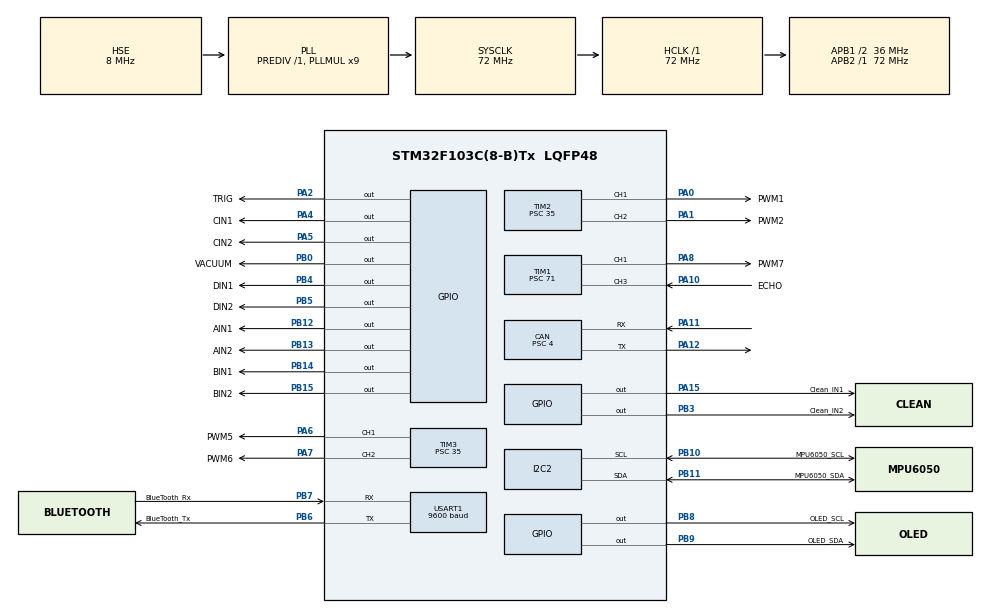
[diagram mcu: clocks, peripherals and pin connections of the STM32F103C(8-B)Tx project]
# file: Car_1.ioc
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CAN.ABOM=DISABLE
CAN.BS1=CAN_BS1_11TQ
CAN.BS2=CAN_BS2_6TQ
CAN.CalculateBaudRate=500000
CAN.CalculateTimeBit=2000
CAN.CalculateTimeQuantum=111.11111111111111
CAN.NART=DISABLE
CAN.Prescaler=4
I2C2.I2C_Mode=I2C_Fast
Mcu.Family=STM32F1
Mcu.Name=STM32F103C(8-B)Tx
Mcu.Package=LQFP48
NVIC.I2C2_EV_IRQn=true\:0\:0\:false\:false\:true\:true\:true\:true
NVIC.PriorityGroup=NVIC_PRIORITYGROUP_4
NVIC.USART1_IRQn=true\:0\:0\:false\:false\:true\:true\:true\:true
NVIC.USB_LP_CAN1_RX0_IRQn=true\:0\:0\:false\:false\:true\:true\:true\:true
PA0-WKUP.GPIO_Label=PWM1
PA0-WKUP.GPIO_Speed=GPIO_SPEED_FREQ_HIGH
PA0-WKUP.Signal=S_TIM2_CH1_ETR
PA1.GPIO_Label=PWM2
PA1.GPIO_Speed=GPIO_SPEED_FREQ_HIGH
PA1.Signal=S_TIM2_CH2
PA10.GPIO_Label=ECHO
PA10.Signal=S_TIM1_CH3
PA11.Mode=CAN_Activate
PA11.Signal=CAN_RX
PA12.Mode=CAN_Activate
PA12.Signal=CAN_TX
PA13.Mode=Serial_Wire
PA13.Signal=SYS_JTMS-SWDIO
PA14.Mode=Serial_Wire
PA14.Signal=SYS_JTCK-SWCLK
PA15.GPIO_Label=Clean_IN1
PA15.Signal=GPIO_Output
PA2.GPIO_Label=TRIG
PA2.Signal=GPIO_Output
PA4.GPIO_Label=CIN1
PA4.Signal=GPIO_Output
PA5.GPIO_Label=CIN2
PA5.Signal=GPIO_Output
PA6.GPIO_Label=PWM5
PA6.GPIO_Speed=GPIO_SPEED_FREQ_HIGH
PA6.Signal=S_TIM3_CH1
PA7.GPIO_Label=PWM6
PA7.GPIO_Speed=GPIO_SPEED_FREQ_HIGH
PA7.Signal=S_TIM3_CH2
PA8.GPIO_Label=PWM7
PA8.GPIO_Speed=GPIO_SPEED_FREQ_HIGH
PA8.Signal=S_TIM1_CH1
PB0.GPIO_Label=VACUUM
PB0.Signal=GPIO_Output
PB10.GPIO_Label=MPU6050_SCL
PB10.Mode=I2C
PB10.Signal=I2C2_SCL
PB11.GPIO_Label=MPU6050_SDA
PB11.Mode=I2C
PB11.Signal=I2C2_SDA
PB12.GPIO_Label=AIN1
PB12.Signal=GPIO_Output
PB13.GPIO_Label=AIN2
PB13.Signal=GPIO_Output
PB14.GPIO_Label=BIN1
PB14.Signal=GPIO_Output
PB15.GPIO_Label=BIN2
PB15.Signal=GPIO_Output
PB3.GPIO_Label=Clean_IN2
PB3.Signal=GPIO_Output
PB4.GPIO_Label=DIN1
PB4.Signal=GPIO_Output
PB5.GPIO_Label=DIN2
PB5.Signal=GPIO_Output
PB6.GPIO_Label=BlueTooth_Tx
PB6.Mode=Asynchronous
PB6.Signal=USART1_TX
PB7.GPIO_Label=BlueTooth_Rx
PB7.Mode=Asynchronous
PB7.Signal=USART1_RX
PB8.GPIO_Label=OLED_SCL
PB8.GPIO_ModeDefaultOutputPP=GPIO_MODE_OUTPUT_OD
PB8.GPIO_PuPd=GPIO_PULLUP
PB8.GPIO_Speed=GPIO_SPEED_FREQ_HIGH
PB8.PinState=GPIO_PIN_SET
PB8.Signal=GPIO_Output
PB9.GPIO_Label=OLED_SDA
PB9.GPIO_ModeDefaultOutputPP=GPIO_MODE_OUTPUT_OD
PB9.GPIO_PuPd=GPIO_PULLUP
PB9.GPIO_Speed=GPIO_SPEED_FREQ_HIGH
PB9.PinState=GPIO_PIN_SET
PB9.Signal=GPIO_Output
PC14-OSC32_IN.Mode=LSE-External-Oscillator
PC14-OSC32_IN.Signal=RCC_OSC32_IN
PC15-OSC32_OUT.Mode=LSE-External-Oscillator
PC15-OSC32_OUT.Signal=RCC_OSC32_OUT
PD0-OSC_IN.Mode=HSE-External-Oscillator
PD0-OSC_IN.Signal=RCC_OSC_IN
PD1-OSC_OUT.Mode=HSE-External-Oscillator
PD1-OSC_OUT.Signal=RCC_OSC_OUT
ProjectManager.HeapSize=0x200
ProjectManager.StackSize=0x400
ProjectManager.TargetToolchain=MDK-ARM V5.32
RCC.AHBFreq_Value=72000000
RCC.APB1CLKDivider=RCC_HCLK_DIV2
RCC.APB1Freq_Value=36000000
RCC.APB1TimFreq_Value=72000000
RCC.APB2Freq_Value=72000000
RCC.APB2TimFreq_Value=72000000
RCC.HCLKFreq_Value=72000000
RCC.PLLMUL=RCC_PLL_MUL9
RCC.PLLSourceVirtual=RCC_PLLSOURCE_HSE
RCC.SYSCLKFreq_VALUE=72000000
RCC.SYSCLKSource=RCC_SYSCLKSOURCE_PLLCLK
RCC.USBFreq_Value=72000000
SH.S_TIM1_CH1.0=TIM1_CH1,PWM Generation1 CH1
SH.S_TIM1_CH3.0=TIM1_CH3,Input_Capture3_from_TI3
SH.S_TIM2_CH1_ETR.0=TIM2_CH1,PWM Generation1 CH1
SH.S_TIM2_CH2.0=TIM2_CH2,PWM Generation2 CH2
SH.S_TIM3_CH1.0=TIM3_CH1,PWM Generation1 CH1
SH.S_TIM3_CH2.0=TIM3_CH2,PWM Generation2 CH2
TIM1.Channel-Input_Capture3_from_TI3=TIM_CHANNEL_3
TIM1.Channel-Input_Capture4_from_TI3_63=TIM_CHANNEL_4
TIM1.Channel-PWM\ Generation1\ CH1=TIM_CHANNEL_1
TIM1.ICPolarity_CH4=TIM_INPUTCHANNELPOLARITY_FALLING
TIM1.Period=19999
TIM1.Prescaler=71
TIM2.AutoReloadPreload=TIM_AUTORELOAD_PRELOAD_ENABLE
TIM2.Channel-PWM\ Generation1\ CH1=TIM_CHANNEL_1
TIM2.Channel-PWM\ Generation2\ CH2=TIM_CHANNEL_2
TIM2.Period=99
TIM2.Prescaler=35
TIM3.Channel-PWM\ Generation1\ CH1=TIM_CHANNEL_1
TIM3.Channel-PWM\ Generation2\ CH2=TIM_CHANNEL_2
TIM3.Period=99
TIM3.Prescaler=35
USART1.BaudRate=9600
USART1.VirtualMode=VM_ASYNC
VP_TIM1_VS_indirect_ch3.Mode=Input_Capture4_from_TI3_63
board=custom

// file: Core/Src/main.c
/* USER CODE BEGIN Header */
/**
  ******************************************************************************
  * @file           : main.c
  * @brief          : Main program body
  ******************************************************************************
  * @attention
  *
  * Copyright (c) 2026 STMicroelectronics.
  * All rights reserved.
  *
  * This software is licensed under terms that can be found in the LICENSE file
  * in the root directory of this software component.
  * If no LICENSE file comes with this software, it is provided AS-IS.
  *
  ******************************************************************************
  */
/* USER CODE END Header */
#include "main.h"
#include "can.h"
#include "i2c.h"
#include "tim.h"
#include "usart.h"
#include "gpio.h"

/* USER CODE BEGIN Includes */
#include "FreeRTOS_Task.h"
#include "OLED.h"
/* USER CODE END Includes */

void SystemClock_Config(void);

int main(void)
{

  /* MCU Configuration--------------------------------------------------------*/

  /* Reset of all peripherals, Initializes the Flash interface and the Systick. */
  HAL_Init();

  /* Configure the system clock */
  SystemClock_Config();

  /* Initialize all configured peripherals */
  MX_GPIO_Init();
  MX_USART1_UART_Init();
  MX_TIM1_Init();
  MX_TIM2_Init();
  MX_TIM3_Init();
  MX_I2C2_Init();
  MX_CAN_Init();
  /* USER CODE BEGIN 2 */

  //启动FreeRTOS => 后续的代码都不执行
  FreeRTOS_start();

  /* USER CODE END 2 */

  /* Infinite loop */
  while (1)
  {

  }
}

void SystemClock_Config(void)
{
  RCC_OscInitTypeDef RCC_OscInitStruct = {0};
  RCC_ClkInitTypeDef RCC_ClkInitStruct = {0};

  /** Initializes the RCC Oscillators according to the specified parameters
  * in the RCC_OscInitTypeDef structure.
  */
  RCC_OscInitStruct.OscillatorType = RCC_OSCILLATORTYPE_HSE;
  RCC_OscInitStruct.HSEState = RCC_HSE_ON;
  RCC_OscInitStruct.HSEPredivValue = RCC_HSE_PREDIV_DIV1;
  RCC_OscInitStruct.HSIState = RCC_HSI_ON;
  RCC_OscInitStruct.PLL.PLLState = RCC_PLL_ON;
  RCC_OscInitStruct.PLL.PLLSource = RCC_PLLSOURCE_HSE;
  RCC_OscInitStruct.PLL.PLLMUL = RCC_PLL_MUL9;
  if (HAL_RCC_OscConfig(&RCC_OscInitStruct) != HAL_OK)
  {
    Error_Handler();
  }

  /** Initializes the CPU, AHB and APB buses clocks
  */
  RCC_ClkInitStruct.ClockType = RCC_CLOCKTYPE_HCLK|RCC_CLOCKTYPE_SYSCLK
                              |RCC_CLOCKTYPE_PCLK1|RCC_CLOCKTYPE_PCLK2;
  RCC_ClkInitStruct.SYSCLKSource = RCC_SYSCLKSOURCE_PLLCLK;
  RCC_ClkInitStruct.AHBCLKDivider = RCC_SYSCLK_DIV1;
  RCC_ClkInitStruct.APB1CLKDivider = RCC_HCLK_DIV2;
  RCC_ClkInitStruct.APB2CLKDivider = RCC_HCLK_DIV1;

  if (HAL_RCC_ClockConfig(&RCC_ClkInitStruct, FLASH_LATENCY_2) != HAL_OK)
  {
    Error_Handler();
  }
}

void Error_Handler(void)
{
  __disable_irq();
  while (1)
  {
  }
}
